# M460_v1 register map
File version: 1.0
Registers are 32-bit, read-write, reset 0x0 unless marked. A register's access mark holds for its fields unless they carry their own. Offsets are from the block's base; [hi:lo] are bit positions; {n}, {i} and the like mark numbered series; 'fields as' and 'values as' point back to an identical list.

## TMR01 — TIMER Register Map
Base 0x40050000
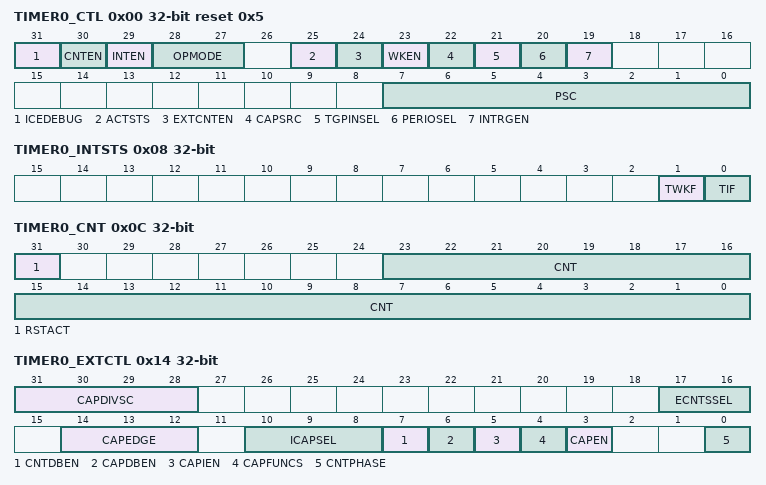
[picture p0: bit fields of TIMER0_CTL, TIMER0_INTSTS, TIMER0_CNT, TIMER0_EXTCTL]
0x00 TIMER0_CTL reset 0x5 — Timer0 Control Register
  [31] ICEDEBUG — ICE Debug Mode Acknowledge Disable Bit (Write Protect). TIMER counter will keep going no matter CPU is held by ICE or not. Note: This bit is write protected. Refer to the SYS_REGLCTL register.
    0=ICE debug mode acknowledgement effects TIMER counting; 1=ICE debug mode acknowledgement Disabled
  [30] CNTEN — Timer Counting Enable Bit. Note 3: Set enable/disable this bit needs 2 * TMR_CLK period to become active, user can read ACTSTS (TIMERx_CTL[25]) to check enable/disable command is completed or not.
    0=Stops/Suspends counting; 1=Starts counting
  [29] INTEN — Timer Time-out Interrupt Enable Bit. Note: If this bit is enabled, when the timer time-out interrupt flag TIF is set to 1, the timer interrupt signal is generated and inform to CPU.
    0=Timer time-out interrupt Disabled; 1=Timer time-out interrupt Enabled
  [28:27] OPMODE — Timer Counting Mode Select
    0=The timer controller is operated in One-shot mode; 1=The timer controller is operated in Periodic mode; 2=The timer controller is operated in Toggle-output mode; 3=The timer controller is operated in Continuous Counting mode
  [25] ACTSTS ro — Timer Active Status Bit (Read Only). This bit indicates the 24-bit up counter status. Note: This bit may active when CNT 0 transition to CNT 1.
    0=24-bit up counter is not active; 1=24-bit up counter is active
  [24] EXTCNTEN — Event Counter Mode Enable Bit. This bit is for event counting function enabled. Note: When timer is used as an event counter, this bit should be set to 1 and select PCLK as timer clock source.
    0=Event counter mode Disabled; 1=Event counter mode Enabled
  [23] WKEN — Wake-up Function Enable Bit. If this bit is set to 1, while timer interrupt flag TIF (TIMERx_INTSTS[0]) is 1 and INTEN (TIMERx_CTL[29]) is enabled, the timer interrupt signal will generate a wake-up trigger event to CPU.
    0=Wake-up function Disabled if timer interrupt signal generated; 1=Wake-up function Enabled if timer interrupt signal generated
  [22] CAPSRC — Capture Source Selection
    0=Capture Function source is from TMx_EXT (x= 0~3) pin; 1=Capture Function source is from internal ACMP output signal, internal clock source (HIRC, LIRC) or external clock (HXT, LXT)
  [21] TGPINSEL — Toggle-output Pin Select
    0=Toggle mode output to TMx (Timer Event Counter Pin); 1=Toggle mode output to TMx_EXT (Timer External Capture Pin)
  [20] PERIOSEL — Periodic Mode Behavior Selection Enable Bit. If updated CMPDAT value CNT, CNT will be reset to default value.
    0=The behavior selection in periodic mode is Disabled; 1=The behavior selection in periodic mode is Enabled
  [19] INTRGEN — Inter-Timer Trigger Mode Enable Bit. Setting this bit will enable the inter-timer trigger capture function. The Timer0/2 will be in event counter mode and counting with external clock source or event.Also, Timer1/3 will be in trigger-counting mode of capture function. Note: For Timer1/3, this bit is ignored and the read back value is always 0.
    0=Inter-Timer Trigger Capture mode Disabled; 1=Inter-Timer Trigger Capture mode Enabled
  [7:0] PSC — Prescale Counter. Note: Update prescale counter value will reset internal 8-bit prescale counter and 24-bit up counter value.
0x04 TIMER0_CMP — Timer0 Comparator Register
  [23:0] CMPDAT — Timer Comparator Value. CMPDAT is a 24-bit compared value register. When the internal 24-bit up counter value is equal to CMPDAT value, the TIF (TIMERx_INTSTS [0] Timer Interrupt Flag) will be set to 1. Note 1: Never write 0x0 or 0x1 in CMPDAT field, or the core will run into unknown state. Note 2: When timer is operating at continuous counting mode, the 24-bit up counter will keep counting continuously even if user writes a new value into CMPDAT field. But if timer is operating at other modes, the 24-bit up counter will restart counting from 0 and using newest CMPDAT value to be the timer compared value while user writes a new value into CMPDAT field.
0x08 TIMER0_INTSTS — Timer0 Interrupt Status Register
  [1] TWKF — Timer Wake-up Flag. This bit indicates the interrupt wake-up flag status of timer. Note: This bit is cleared by writing 1 to it.
    0=Timer does not cause CPU wake-up; 1=CPU wake-up from Idle or Power-down mode if timer time-out interrupt signal generated
  [0] TIF — Timer Interrupt Flag. This bit indicates the interrupt flag status of timer while 24-bit timer up counter CNT (TIMERx_CNT[23:0]) value reaches CMPDAT (TIMERx_CMP[23:0]) value. Note: This bit is cleared by writing 1 to it.
    0=No effect; 1=CNT value matches the CMPDAT value
0x0C TIMER0_CNT — Timer0 Data Register
  [31] RSTACT ro — Timer Data Register Reset Active (Read Only). This bit indicates if the counter reset operation active. When user writes this CNT register, timer starts to reset its internal 24-bit timer up-counter to 0 and reload 8-bit pre-scale counter. At the same time, timer set this flag to 1 to indicate the counter reset operation is in progress. Once the counter reset operation done, timer clear this bit to 0 automatically.
    0=Reset operation is done; 1=Reset operation triggered by writing TIMERx_CNT is in progress
  [23:0] CNT — Timer Data Register. Read operation. Read this register to get CNT value. For example: If EXTCNTEN (TIMERx_CTL[24]) is 0, user can read CNT value for getting current 24-bit counter value. If EXTCNTEN (TIMERx_CTL[24]) is 1, user can read CNT value for getting current 24-bit event input counter value. Write operation. Writing any value to this register will reset current CNT value to 0 and reload internal 8-bit prescale counter.
0x10 TIMER0_CAP ro — Timer0 Capture Data Register
  [23:0] CAPDAT — Timer Capture Data Register. When CAPEN (TIMERx_EXTCTL[3]) bit is set, the transition on the capture source matches the CAPEDGE (TIMERx_EXTCTL[14:12]) setting, CAPIF (TIMERx_EINTSTS[0]) will be set to 1 and the current timer counter value CNT (TIMERx_CNT[23:0]) will be auto-loaded into this CAPDAT field.
0x14 TIMER0_EXTCTL — Timer0 External Control Register
  [31:28] CAPDIVSC — Timer Capture Source Divider Scale. These bits indicate the divide scale for capture source divider. Note: Sets CAPSRC (TIMERx_CTL[22]) and ICAPSEL (TIMERx_EXTCTL[10:8]) to select capture source.
    0=Capture source/1; 1=Capture source/2; 2=Capture source/4; 3=Capture source/8; 4=Capture source/16; 5=Capture source/32; 6=Capture source/64; 7=Capture source/128; 8=Capture source/256
  [17:16] ECNTSSEL — Event Counter Source Selection to Trigger Event Counter Function
    0=Event Counter input source is from external TMx (x= 0~3) pin; 1=Event Counter input source is from internal USB internal SOF output signal; 2=Event Counter input source is from internal ACMP0 output signal; 3=Event Counter input source is from internal ACMP1 output signal
  [14:12] CAPEDGE — Timer Capture Edge Detect. When the first capture event is generated, the CNT (TIMERx_CNT[23:0]) will be reset to 0 and first CAPDAT (TIMERx_CAP[23:0]) should be to 0. Note: Set CAPSRC (TIMERx_CTL[22]) and ICAPSEL (TIMERx_EXTCTL[10:8]) to select capture source.
    0=Capture event occurred when detect falling edge transfer on capture source; 1=Capture event occurred when detect rising edge transfer on capture source; 2=Capture event occurred when detect both falling and rising edge transfer on capture source, and the first capture event occurred at falling edge transfer; 3=Capture event occurred when detect both rising and falling edge transfer on capture source, and the first capture event occurred at rising edge transfer; 6=First capture event occurred at falling edge, follows capture events are at rising edge transfer on capture source; 7=First capture event occurred at rising edge, follows capture events are at falling edge transfer on capture source
  [10:8] ICAPSEL — Internal Capture Source Select. Note: These bits only available when CAPSRC (TIMERx_CTL[22]) is 1.
    0=Capture Function source is from internal ACMP0 output signal; 1=Capture Function source is from internal ACMP1 output signal; 2=Capture Function source is from HXT; 3=Capture Function source is from LXT; 4=Capture Function source is from HIRC; 5=Capture Function source is from LIRC
  [7] CNTDBEN — Timer External Counter Pin De-bounce Enable Bit. Note: If this bit is enabled, the edge detection of TMx pin is detected with de-bounce circuit.
    0=TMx (x= 0~3) pin de-bounce Disabled; 1=TMx (x= 0~3) pin de-bounce Enabled
  [6] CAPDBEN — Timer Capture De-bounce Enable Bit. Note: If this bit is enabled, the edge detection of TMx_EXT pin or ACMP output is detected with de-bounce circuit.
    0=TMx_EXT (x= 0~3) pin de-bounce or ACMP output de-bounce Disabled; 1=TMx_EXT (x= 0~3) pin de-bounce or ACMP output de-bounce Enabled
  [5] CAPIEN — Timer Capture Interrupt Enable Bit
    0=TMx_EXT (x= 0~3) pin, ACMP, internal clock, or external clock detection Interrupt Disabled; 1=TMx_EXT (x= 0~3) pin, ACMP, internal clock, or external clock detection Interrupt Enabled
  [4] CAPFUNCS — Capture Function Selection. Note 1: When CAPFUNCS is 0 and CAPIF becomes 1, the current 24-bit timer counter value (CNT value) will be saved to CAPDAT field. Note 2: When CAPFUNCS is 1 and CAPIF becomes 1, the current 24-bit timer counter value (CNT value) will be saved to CAPDAT field then CNT value will be reset to 0 immediately.
    0=Capture Mode Enabled; 1=Capture and Reset Mode Enabled
  [3] CAPEN — Timer Capture Function Enable Bit. This bit enables the capture input function.
    0=Timer capture function Disabled; 1=Timer capture function Enabled
  [0] CNTPHASE — Timer External Count Phase
    0=A falling edge of external counting pin will be counted; 1=A rising edge of external counting pin will be counted
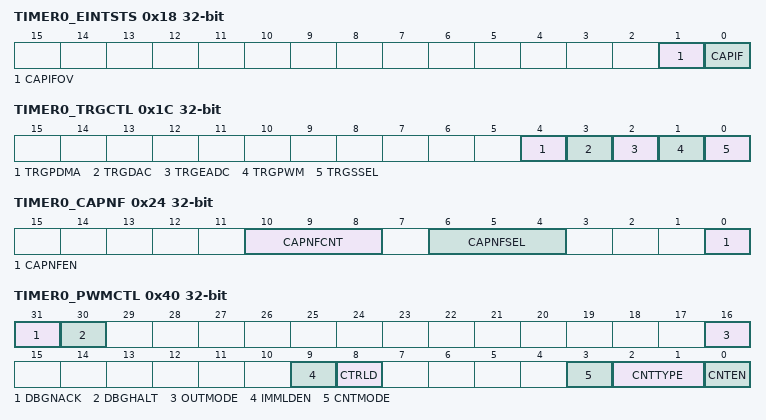
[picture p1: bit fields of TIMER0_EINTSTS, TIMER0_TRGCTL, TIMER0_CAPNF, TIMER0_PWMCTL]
0x18 TIMER0_EINTSTS — Timer0 External Interrupt Status Register
  [1] CAPIFOV ro — Capture Latch Interrupt Flag Overrun Status (Read Only). Note: This bit will be cleared automatically when user clears corresponding CAPIF.
    0=Capture latch happened when the corresponding CAPIF is 0; 1=Capture latch happened when the corresponding CAPIF is 1
  [0] CAPIF — Timer Capture Interrupt Flag. This bit indicates the timer capture interrupt flag status. Note 1: This bit is cleared by writing 1 to it. Note 2: When CAPEN (TIMERx_EXTCTL[3]) bit is set, the transition on the capture source matches the CAPEDGE (TIMERx_EXTCTL[14:12]) setting, this bit will be set to 1 by hardware. Note 3: There is a new incoming capture event detected before CPU clearing the CAPIF status. If the above condition occurred, the timer will keep register TIMERx_CAP unchanged and drop the new capture value.
    0=TMx_EXT (x= 0~3) pin, ACMP, internal clock, or external clock capture interrupt did not occur; 1=TMx_EXT (x= 0~3) pin, ACMP, internal clock, or external clock capture interrupt occurred
0x1C TIMER0_TRGCTL — Timer0 Trigger Control Register
  [4] TRGPDMA — Trigger PDMA Enable Bit. If this bit is set to 1, each timer time-out event or capture event can be triggered PDMA transfer.
    0=Timer interrupt trigger PDMA Disabled; 1=Timer interrupt trigger PDMA Enabled
  [3] TRGDAC — Trigger DAC Enable Bit. If this bit is set to 1, timer time-out interrupt or capture interrupt can be triggered DAC conversion.
    0=Timer interrupt trigger DAC Disabled; 1=Timer interrupt trigger DAC Enabled
  [2] TRGEADC — Trigger EADC Enable Bit. If this bit is set to 1, each timer time-out event or capture event can be triggered EADC conversion.
    0=Timer interrupt trigger EADC Disabled; 1=Timer interrupt trigger EADC Enabled
  [1] TRGPWM — Trigger EPWM and BPWM Enable Bit. If this bit is set to 1, each timer time-out event or capture event can be as EPWM and BPWM counter clock source.
    0=Timer interrupt signal as EPWM and BPWM counter clock source Disabled; 1=Timer interrupt signal as EPWM and BPWM counter clock source Enabled
  [0] TRGSSEL — Trigger Source Select Bit. This bit is used to select internal trigger source is form timer time-out interrupt signal or capture interrupt signal.
    0=Time-out interrupt signal is used to internal trigger EPWM, BPWM, PDMA, DAC, and EADC; 1=Capture interrupt signal is used to internal trigger EPWM, BPWM, PDMA, DAC, and EADC
0x20 TIMER0_ALTCTL — Timer0 Alternative Control Register
  [0] FUNCSEL — Function Selection. Note: When the timer is used as PWM, the clock source of time controller will be forced to PCLKx automatically.
    0=Timer controller is used as timer function; 1=Timer controller is used as PWM function
0x24 TIMER0_CAPNF — Timer0 Capture Input Noise Filter Register
  [10:8] CAPNFCNT — Capture Edge Detector Noise Filter Count. These bits control the capture filter counter to count from 0 to CAPNFCNT.
  [6:4] CAPNFSEL — Capture Edge Detector Noise Filter Clock Selection
    0=Noise filter clock is PCLKx; 1=Noise filter clock is PCLKx/2; 2=Noise filter clock is PCLKx/4; 3=Noise filter clock is PCLKx/8; 4=Noise filter clock is PCLKx/16; 5=Noise filter clock is PCLKx/32; 6=Noise filter clock is PCLKx/64; 7=Noise filter clock is PCLKx/128
  [0] CAPNFEN — Capture Noise Filter Enable
    0=Capture Noise Filter function Disabled; 1=Capture Noise Filter function Enabled
0x40 TIMER0_PWMCTL — Timer0 PWM Control Register
  [31] DBGNACK — ICE Debug Mode Acknowledge Disable Bit (Write Protect). PWM output pin will keep output no matter ICE debug mode acknowledged or not. Note: This bit is write protected. Refer toSYS_REGLCTL register.
    0=ICE debug mode acknowledgement effects PWM output; 1=ICE debug mode acknowledgement disabled
  [30] DBGHALT — ICE Debug Mode Counter Halt (Write Protect). If debug mode counter halt is enabled, PWM counter will keep current value until exit ICE debug mode. Note: This bit is write protected. Refer toSYS_REGLCTL register.
    0=ICE debug mode counter halt disable; 1=ICE debug mode counter halt enable
  [16] OUTMODE — PWM Output Mode. This bit controls the output mode of corresponding PWM channel.
    0=PWM independent mode; 1=PWM complementary mode
  [9] IMMLDEN — Immediately Load Enable Bit. Note: If IMMLDEN is enabled, CTRLD will be invalid.
    0=PERIOD will load to PBUF when current PWM period is completed no matter CTRLD is enabled/disabled. If CTRLD is disabled, CMP will load to CMPBUF when current PWM period is completed; if CTRLD is enabled in up-down count type, CMP will load to CMPBUF at the center point of current period; 1=PERIOD/CMP will load to PBUF/CMPBUF immediately when user writes PERIOD/CMP and current counter count is completed
  [8] CTRLD — Center Re-load. In up-down count type, PERIOD will load to PBUF when current PWM period is completed always and CMP will load to CMPBUF at the center point of current period.
  [3] CNTMODE — PWM Counter Mode
    0=Auto-reload mode; 1=One-shot mode
  [2:1] CNTTYPE — PWM Counter Behavior Type
    0=Up count type; 1=Down count type; 2=Up-down count type
  [0] CNTEN — PWM Counter Enable Bit
    0=PWM counter and clock prescale Stop Running; 1=PWM counter and clock prescale Start Running
0x44 TIMER0_PWMCLKSRC — Timer0 PWM Counter Clock Source Register
  [2:0] CLKSRC — PWM Counter Clock Source Select. The PWM counter clock source can be selected from TMRx_CLK or internal timer time-out or capture event. Note: If TIMER0 PWM function is enabled, the PWM counter clock source can be selected from TMR0_CLK, TIMER1 interrupt events, TIMER2 interrupt events, or TIMER3 interrupt events.
    0=TMRx_CLK; {v}=Internal TIMER{v-1} time-out or capture event (v=1..4)
0x48 TIMER0_PWMCLKPSC — Timer0 PWM Counter Clock Pre-scale Register
  [11:0] CLKPSC — PWM Counter Clock Pre-scale. The active clock of PWM counter is decided by counter clock prescale and divided by (CLKPSC + 1). If CLKPSC is 0, then there is no scaling in PWM counter clock source.
0x4C TIMER0_PWMCNTCLR — Timer0 PWM Clear Counter Register
  [0] CNTCLR — Clear PWM Counter Control Bit. It is automatically cleared by hardware.
    0=No effect; 1=Clear 16-bit PWM counter to 0x10000 in up and up-down count type and reset counter value to PERIOD in down count type
0x50 TIMER0_PWMPERIOD
  [15:0] PERIOD — PWM Period Register. In up count type: PWM counter counts from 0 to PERIOD, and restarts from 0. In down count type: PWM counter counts from PERIOD to 0, and restarts from PERIOD. In up-down count type: PWM counter counts from 0 to PERIOD, then decrements to 0 and repeats again. In up and down count type: Note: User should take care DIRF (TIMERx_PWMCNT[16]) bit in up/down/up-down count type to monitor current counter direction in each count type.
0x54 TIMER0_PWMCMPDAT — Timer0 PWM Comparator Register
  [15:0] CMP — PWM Comparator Register. PWM CMP is used to compare with PWM CNT to generate PWM output waveform, interrupt events and trigger EADC to start conversion.
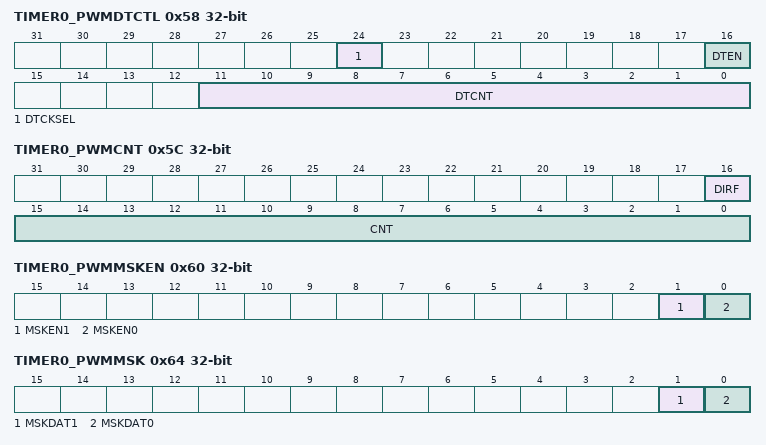
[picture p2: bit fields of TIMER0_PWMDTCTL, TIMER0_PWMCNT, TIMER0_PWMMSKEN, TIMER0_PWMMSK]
0x58 TIMER0_PWMDTCTL — Timer0 PWM Dead-Time Control Register
  [24] DTCKSEL — Dead-time Clock Select (Write Protect). Note: This bit is write protected. Refer toSYS_REGLCTL register.
    0=Dead-time clock source from TMRx_PWMCLK without counter clock prescale; 1=Dead-time clock source from TMRx_PWMCLK with counter clock prescale
  [16] DTEN — Enable Dead-time Insertion for PWMx_CH0 and PWMx_CH1 (Write Protect). Dead-time insertion function is only active when PWM complementary mode is enabled. If dead- time insertion is inactive, the outputs of PWMx_CH0 and PWMx_CH1 are complementary without any delay. Note: This bit is write protected. Refer toSYS_REGLCTL register.
    0=Dead-time insertion Disabled on the pin pair; 1=Dead-time insertion Enabled on the pin pair
  [11:0] DTCNT — Dead-time Counter (Write Protect). The dead-time can be calculated from the following two formulas: Note: This bit is write protected. Refer toSYS_REGLCTL register.
0x5C TIMER0_PWMCNT ro — Timer0 PWM Counter Register
  [16] DIRF — PWM Counter Direction Indicator Flag (Read Only)
    0=Counter is active in down count; 1=Counter is active up count
  [15:0] CNT — PWM Counter Value Register (Read Only). User can monitor CNT to know the current counter value in 16-bit period counter.
0x60 TIMER0_PWMMSKEN — Timer0 PWM Output Mask Enable Register
  [1] MSKEN1 — PWMx_CH1 Output Mask Enable Bit. The PWMx_CH1 output signal will be masked when this bit is enabled. The PWMx_CH1 will output MSKDAT1 (TIMERx_PWMMSK[1]) data.
    0=PWMx_CH1 output signal is non-masked; 1=PWMx_CH1 output signal is masked and output MSKDAT1 data
  [0] MSKEN0 — PWMx_CH0 Output Mask Enable Bit. The PWMx_CH0 output signal will be masked when this bit is enabled. The PWMx_CH0 will output MSKDAT0 (TIMERx_PWMMSK[0]) data.
    0=PWMx_CH0 output signal is non-masked; 1=PWMx_CH0 output signal is masked and output MSKDAT0 data
0x64 TIMER0_PWMMSK — Timer0 PWM Output Mask Data Control Register
  [1] MSKDAT1 — PWMx_CH1 Output Mask Data Control Bit
    0=Output logic Low to PWMx_CH1; 1=Output logic High to PWMx_CH1
  [0] MSKDAT0 — PWMx_CH0 Output Mask Data Control Bit
    0=Output logic Low to PWMx_CH0; 1=Output logic High to PWMx_CH0
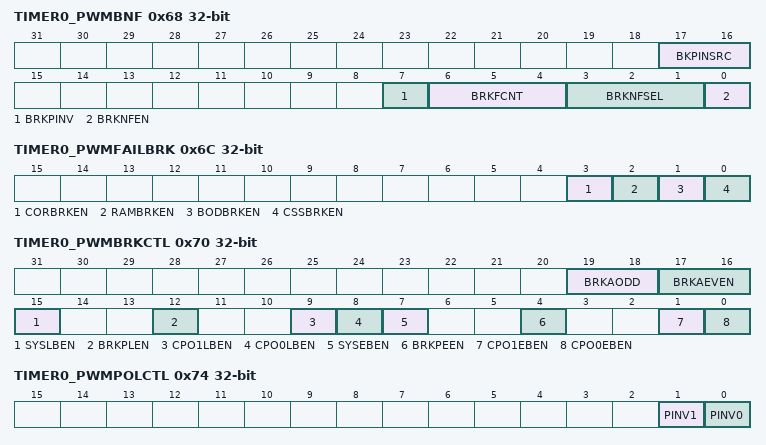
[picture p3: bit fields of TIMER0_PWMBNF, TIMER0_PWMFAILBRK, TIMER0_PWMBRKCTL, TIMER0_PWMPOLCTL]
0x68 TIMER0_PWMBNF — Timer0 PWM Brake Pin Noise Filter Register
  [17:16] BKPINSRC — Brake Pin Source Select
    0=Brake pin source comes from PWM0_BRAKE0 pin; 1=Brake pin source comes from PWM0_BRAKE1 pin; 2=Brake pin source comes from PWM1_BRAKE0 pin; 3=Brake pin source comes from PWM1_BRAKE1 pin
  [7] BRKPINV — Brake Pin Detection Value Control Bit
    0=Brake pin event will be detected if PWMx_BRAKEy pin status transfer from low to high in edge-detect, or pin status is high in level-detect; 1=Brake pin event will be detected if PWMx_BRAKEy pin status transfer from high to low in edge-detect, or pin status is low in level-detect
  [6:4] BRKFCNT — Brake Pin Noise Filter Count. The fields are used to control the active noise filter sample time.
  [3:1] BRKNFSEL — Brake Pin Noise Filter Clock Selection
    values as TIMER0_CAPNF.CAPNFSEL
  [0] BRKNFEN — Brake Pin Noise Filter Enable Bit
    0=Pin noise filter detect of PWMx_BRAKEy Disabled; 1=Pin noise filter detect of PWMx_BRAKEy Enabled
0x6C TIMER0_PWMFAILBRK — Timer0 PWM System Fail Brake Control Register
  [3] CORBRKEN — Core Lockup Detection Trigger PWM Brake Function Enable Bit
    0=Brake Function triggered by core lockup event Disabled; 1=Brake Function triggered by core lockup event Enabled
  [2] RAMBRKEN — SRAM Parity Error Detection Trigger PWM Brake Function Enable Bit
    0=Brake Function triggered by SRAM parity error detection Disabled; 1=Brake Function triggered by SRAM parity error detection Enabled
  [1] BODBRKEN — Brown-out Detection Trigger PWM Brake Function Enable Bit
    0=Brake Function triggered by BOD event Disabled; 1=Brake Function triggered by BOD event Enabled
  [0] CSSBRKEN — Clock Security System Detection Trigger PWM Brake Function Enable Bit
    0=Brake Function triggered by clock fail detection Disabled; 1=Brake Function triggered by clock fail detection Enabled
0x70 TIMER0_PWMBRKCTL — Timer0 PWM Brake Control Register
  [19:18] BRKAODD — PWM Brake Action Select for PWMx_CH1 (Write Protect). Note: This bit is write protected. Refer toSYS_REGLCTL register.
    0=PWMx_BRAKEy brake event will not affect PWMx_CH1 output; 1=PWMx_CH1 output tri-state when PWMx_BRAKEy brake event happened; 2=PWMx_CH1 output low level when PWMx_BRAKEy brake event happened; 3=PWMx_CH1 output high level when PWMx_BRAKEy brake event happened
  [17:16] BRKAEVEN — PWM Brake Action Select for PWMx_CH0 (Write Protect). Note: This bit is write protected. Refer toSYS_REGLCTL register.
    0=PWMx_BRAKEy brake event will not affect PWMx_CH0 output; 1=PWMx_CH0 output tri-state when PWMx_BRAKEy brake event happened; 2=PWMx_CH0 output low level when PWMx_BRAKEy brake event happened; 3=PWMx_CH0 output high level when PWMx_BRAKEy brake event happened
  [15] SYSLBEN — Enable System Fail As Level-detect Brake Source (Write Protect). Note: This bit is write protected. Refer toSYS_REGLCTL register.
    0=System fail condition as level-detect brake source Disabled; 1=System fail condition as level-detect brake source Enabled
  [12] BRKPLEN — Enable PWMx_BRAKEy Pin As Level-detect Brake Source (Write Protect). Note: This bit is write protected. Refer toSYS_REGLCTL register.
    0=PWMx_BRAKEy pin event as level-detect brake source Disabled; 1=PWMx_BRAKEy pin event as level-detect brake source Enabled
  [9] CPO1LBEN — Enable Internal ACMP1_O Digital Output As Level-detect Brake Source (Write Protect). Note 1: Only internal ACMP1_O signal from low to high will be detected as brake event. Note 2: This bit is write protected. Refer toSYS_REGLCTL register.
    0=Internal ACMP1_O signal as level-detect brake source Disabled; 1=Internal ACMP1_O signal as level-detect brake source Enabled
  [8] CPO0LBEN — Enable Internal ACMP0_O Digital Output As Level-detect Brake Source (Write Protect). Note 1: Only internal ACMP0_O signal from low to high will be detected as brake event. Note 2: This bit is write protected. Refer toSYS_REGLCTL register.
    0=Internal ACMP0_O signal as level-detect brake source Disabled; 1=Internal ACMP0_O signal as level-detect brake source Enabled
  [7] SYSEBEN — Enable System Fail As Edge-detect Brake Source (Write Protect). Note: This bit is write protected. Refer toSYS_REGLCTL register.
    0=System fail condition as edge-detect brake source Disabled; 1=System fail condition as edge-detect brake source Enabled
  [4] BRKPEEN — Enable PWMx_BRAKEy Pin As Edge-detect Brake Source (Write Protect). Note: This bit is write protected. Refer toSYS_REGLCTL register.
    0=PWMx_BRAKEy pin event as edge-detect brake source Disabled; 1=PWMx_BRAKEy pin event as edge-detect brake source Enabled
  [1] CPO1EBEN — Enable Internal ACMP1_O Digital Output As Edge-detect Brake Source (Write Protect). Note 1: Only internal ACMP1_O signal from low to high will be detected as brake event. Note 2: This bit is write protected. Refer toSYS_REGLCTL register.
    0=Internal ACMP1_O signal as edge-detect brake source Disabled; 1=Internal ACMP1_O signal as edge-detect brake source Enabled
  [0] CPO0EBEN — Enable Internal ACMP0_O Digital Output As Edge-detect Brake Source (Write Protect). Note 1: Only internal ACMP0_O signal from low to high will be detected as brake event. Note 2: This bit is write protected. Refer toSYS_REGLCTL register.
    0=Internal ACMP0_O signal as edge-detect brake source Disabled; 1=Internal ACMP0_O signal as edge-detect brake source Enabled
0x74 TIMER0_PWMPOLCTL — Timer0 PWM Pin Output Polar Control Register
  [1] PINV1 — PWMx_CH1 Output Pin Polar Control Bit. The bit is used to control polarity state of PWMx_CH1 output pin.
    0=PWMx_CH1 output pin polar inverse Disabled; 1=PWMx_CH1 output pin polar inverse Enabled
  [0] PINV0 — PWMx_CH0 Output Pin Polar Control Bit. The bit is used to control polarity state of PWMx_CH0 output pin.
    0=PWMx_CH0 output pin polar inverse Disabled; 1=PWMx_CH0 output pin polar inverse Enabled
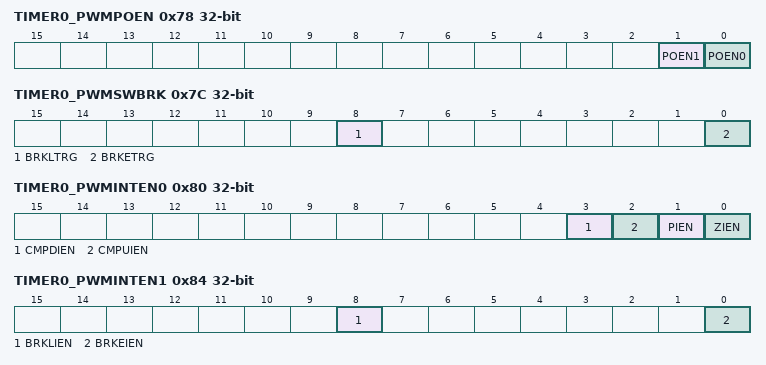
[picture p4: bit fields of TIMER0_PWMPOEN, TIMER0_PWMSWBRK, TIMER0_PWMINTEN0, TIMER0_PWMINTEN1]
0x78 TIMER0_PWMPOEN — Timer0 PWM Pin Output Enable Register
  [1] POEN1 — PWMx_CH1 Output Pin Enable Bit
    0=PWMx_CH1 pin at tri-state mode; 1=PWMx_CH1 pin in output mode
  [0] POEN0 — PWMx_CH0 Output Pin Enable Bit
    0=PWMx_CH0 pin at tri-state mode; 1=PWMx_CH0 pin in output mode
0x7C TIMER0_PWMSWBRK wo — Timer0 PWM Software Trigger Brake Control Register
  [8] BRKLTRG — Software Trigger Level-detect Brake Source (Write Only) (Write Protect). Write 1 to this bit will trigger PWM level-detect brake source, then BRKLIF0 and BRKLIF1 will be set to 1 automatically in TIMERx_PWMINTSTS1 register. Note: This bit is write protected. Refer toSYS_REGLCTL register.
  [0] BRKETRG — Software Trigger Edge-detect Brake Source (Write Only) (Write Protect). Write 1 to this bit will trigger PWM edge-detect brake source, then BRKEIF0 and BRKEIF1 will be set to 1 automatically in TIMERx_PWMINTSTS1 register. Note: This bit is write protected. Refer toSYS_REGLCTL register.
0x80 TIMER0_PWMINTEN0 — Timer0 PWM Interrupt Enable Register 0
  [3] CMPDIEN — PWM Compare Down Count Interrupt Enable Bit
    0=Compare down count interrupt Disabled; 1=Compare down count interrupt Enabled
  [2] CMPUIEN — PWM Compare Up Count Interrupt Enable Bit
    0=Compare up count interrupt Disabled; 1=Compare up count interrupt Enabled
  [1] PIEN — PWM Period Point Interrupt Enable Bit. Note: In up-down count type, period point means the center point of current PWM period.
    0=Period point interrupt Disabled; 1=Period point interrupt Enabled
  [0] ZIEN — PWM Zero Point Interrupt Enable Bit
    0=Zero point interrupt Disabled; 1=Zero point interrupt Enabled
0x84 TIMER0_PWMINTEN1 — Timer0 PWM Interrupt Enable Register 1
  [8] BRKLIEN — PWM Level-detect Brake Interrupt Enable Bit (Write Protect). Note: This bit is write protected. Refer toSYS_REGLCTL register.
    0=PWM level-detect brake interrupt Disabled; 1=PWM level-detect brake interrupt Enabled
  [0] BRKEIEN — PWM Edge-detect Brake Interrupt Enable Bit (Write Protect). Note: This bit is write protected. Refer toSYS_REGLCTL register.
    0=PWM edge-detect brake interrupt Disabled; 1=PWM edge-detect brake interrupt Enabled
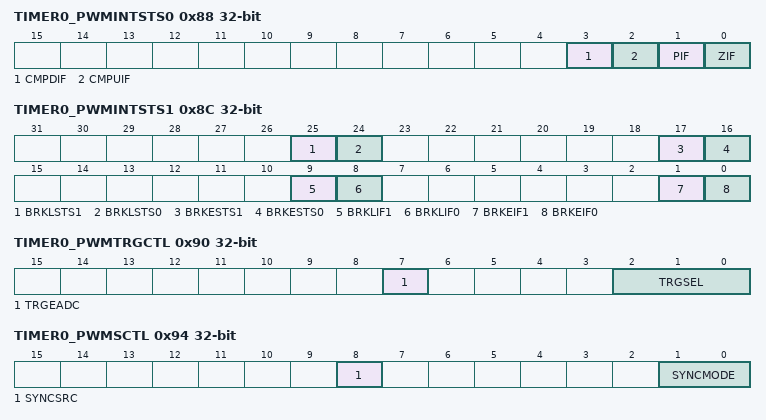
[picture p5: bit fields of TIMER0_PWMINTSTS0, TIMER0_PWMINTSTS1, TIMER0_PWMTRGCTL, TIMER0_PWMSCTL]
0x88 TIMER0_PWMINTSTS0 — Timer0 PWM Interrupt Status Register 0
  [3] CMPDIF — PWM Compare Down Count Interrupt Flag. This bit is set by hardware when TIMERx_PWM counter in down count direction and reaches CMP. Note 1: If CMP is equal to PERIOD, there is no CMPDIF flag in down count type. Note 2: This bit is cleared by writing 1 to it.
  [2] CMPUIF — PWM Compare Up Count Interrupt Flag. This bit is set by hardware when TIMERx_PWM counter in up count direction and reaches CMP. Note 1: If CMP is equal to PERIOD, there is no CMPUIF flag in up count type and up-down count type. Note 2: This bit is cleared by writing 1 to it.
  [1] PIF — PWM Period Point Interrupt Flag. This bit is set by hardware when TIMERx_PWM counter reaches PERIOD. Note 1: In up-down count type, PIF flag means the center point flag of current PWM period. Note 2: This bit is cleared by writing 1 to it.
  [0] ZIF — PWM Zero Point Interrupt Flag. This bit is set by hardware when TIMERx_PWM counter reaches 0. Note: This bit is cleared by writing 1 to it.
0x8C TIMER0_PWMINTSTS1 — Timer0 PWM Interrupt Status Register 1
  [25] BRKLSTS1 ro — Level-detect Brake Status of PWMx_CH1 (Read Only). Note: If TIMERx_PWM level-detect brake source has released, both PWMx_CH0 and PWMx_CH1 will release brake state when current PWM period finished and resume PWMx_CH0 and PWMx_CH1 output waveform start from next full PWM period.
    0=PWMx_CH1 level-detect brake state is released; 1=PWMx_CH1 at level-detect brake state
  [24] BRKLSTS0 ro — Level-detect Brake Status of PWMx_CH0 (Read Only). Note: If TIMERx_PWM level-detect brake source has released, both PWMx_CH0 and PWMx_CH1 will release brake state when current PWM period finished and resume PWMx_CH0 and PWMx_CH1 output waveform start from next full PWM period.
    0=PWMx_CH0 level-detect brake state is released; 1=PWMx_CH0 at level-detect brake state
  [17] BRKESTS1 ro — Edge-detect Brake Status of PWMx_CH1 (Read Only). Note: User can set BRKEIF1 1 to clear BRKEIF1 flag and PWMx_CH1 will release brake state when current PWM period finished and resume PWMx_CH1 output waveform start from next full PWM period.
    0=PWMx_CH1 edge-detect brake state is released; 1=PWMx_CH1 at edge-detect brake state
  [16] BRKESTS0 ro — Edge -detect Brake Status of PWMx_CH0 (Read Only). Note: User can set BRKEIF0 1 to clear BRKEIF0 flag and PWMx_CH0 will release brake state when current PWM period finished and resume PWMx_CH0 output waveform start from next full PWM period.
    0=PWMx_CH0 edge-detect brake state is released; 1=PWMx_CH0 at edge-detect brake state
  [9] BRKLIF1 — Level-detect Brake Interrupt Flag on PWMx_CH1 (Write Protect). Note 1: This bit is cleared by writing 1 to it. Note 2: This bit is write protected. Refer to SYS_REGLCTL register.
    0=PWMx_CH1 level-detect brake event do not happened; 1=PWMx_CH1 level-detect brake event happened
  [8] BRKLIF0 — Level-detect Brake Interrupt Flag on PWMx_CH0 (Write Protect). Note 1: This bit is cleared by writing 1 to it. Note 2: This bit is write protected. Refer to SYS_REGLCTL register.
    0=PWMx_CH0 level-detect brake event do not happened; 1=PWMx_CH0 level-detect brake event happened
  [1] BRKEIF1 — Edge-detect Brake Interrupt Flag PWMx_CH1 (Write Protect). Note 1: This bit is cleared by writing 1 to it. Note 2: This bit is write protected. Refer to SYS_REGLCTL register.
    0=PWMx_CH1 edge-detect brake event do not happened; 1=PWMx_CH1 edge-detect brake event happened
  [0] BRKEIF0 — Edge-detect Brake Interrupt Flag on PWMx_CH0 (Write Protect). Note 1: This bit is cleared by writing 1 to it. Note 2: This bit is write protected. Refer to SYS_REGLCTL register.
    0=PWMx_CH0 edge-detect brake event do not happened; 1=PWMx_CH0 edge-detect brake event happened
0x90 TIMER0_PWMTRGCTL — Timer0 PWM Trigger Control Register
  [7] TRGEADC — PWM Counter Event Trigger EADC Conversion Enable Bit. Note: Set TRGSEL (TIMERx_PWMTRGCTL[2:0]) to select PWM trigger conversion source.
    0=PWM counter event trigger EADC conversion Disabled; 1=PWM counter event trigger EADC conversion Enabled
  [2:0] TRGSEL — PWM Counter Event Source Select to Trigger Conversion
    0=Trigger conversion at zero point (ZIF); 1=Trigger conversion at period point (PIF); 2=Trigger conversion at zero or period point (ZIF or PIF); 3=Trigger conversion at compare up count point (CMPUIF); 4=Trigger conversion at compare down count point (CMPDIF)
0x94 TIMER0_PWMSCTL — Timer0 PWM Synchronous Control Register
  [8] SYNCSRC — PWM Synchronous Counter Start/Clear Source Select. Note 1: If TIMER0/1/2/3 PWM counter synchronous source are from TIMER0, TIMER0_PWMSCTL[8], TIMER1_PWMSCTL[8], TIMER2_PWMSCTL[8] and TIMER3_PWMSCTL[8] should be 0. Note 2: If TIMER0/1/ PWM counter synchronous source are from TIMER0, TIMER0_PWMSCTL[8] and TIMER1_PWMSCTL[8] should be set 0, and TIMER2/3/ PWM counter synchronous source are from TIMER2, TIMER2_PWMSCTL[8] and TIMER3_PWMSCTL[8] should be set 1.
    0=Counter synchronous start/clear by trigger TIMER0_PWMSTRG STRGEN bit; 1=Counter synchronous start/clear by trigger TIMER2_PWMSTRG STRGEN bit
  [1:0] SYNCMODE — PWM Synchronous Mode Enable Select
    0=PWM synchronous function Disabled; 1=PWM synchronous counter start function Enabled; 3=PWM synchronous counter clear function Enabled
0x98 TIMER0_PWMSTRG wo — Timer0 PWM Synchronous Trigger Register
  [0] STRGEN — PWM Counter Synchronous Trigger Enable Bit (Write Only). PMW counter synchronous function is used to make selected PWM channels (including TIMER0/1/2/3 PWM, TIMER0/1 PWM and TIMER2/3 PWM) start counting or clear counter at the same time according to TIMERx_PWMSCTL setting. Note: This bit is only available in TIMER0 and TIMER2.
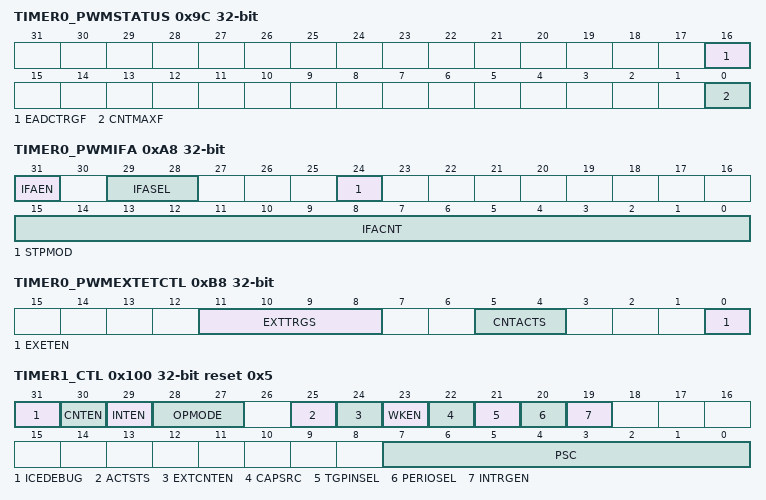
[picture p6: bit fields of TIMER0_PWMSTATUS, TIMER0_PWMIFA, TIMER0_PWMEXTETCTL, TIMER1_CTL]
0x9C TIMER0_PWMSTATUS
  [16] EADCTRGF — Trigger EADC Start Conversion Flag. Note: This bit is cleared by writing 1 to it.
    0=PWM counter event trigger EADC start conversion did not occurred; 1=PWM counter event trigger EADC start conversion occurred
  [0] CNTMAXF — PWM Counter Equal to 0xFFFF Flag. Note: This bit is cleared by writing 1 to it.
    0=The PWM counter value never reached its maximum value 0xFFFF; 1=The PWM counter value has reached its maximum value
0xA0 TIMER0_PWMPBUF ro — Timer0 PWM Period Buffer Register
  [15:0] PBUF — PWM Period Buffer Register (Read Only). Used as PERIOD active register.
0xA4 TIMER0_PWMCMPBUF ro — Timer0 PWM Comparator Buffer Register
  [15:0] CMPBUF — PWM Comparator Buffer Register (Read Only). Used as CMP active register.
0xA8 TIMER0_PWMIFA — Timer0 PWM Interrupt Flag Accumulator Register
  [31] IFAEN — PWM Interrupt Flag Accumulator Enable Bit
    0=PWM interrupt flag accumulator function Disabled; 1=PWM interrupt flag accumulator function Enabled
  [29:28] IFASEL — PWM Interrupt Flag Accumulator Source Select
    0=Accumulate at each PWM zero point; 1=Accumulate at each PWM period point; 2=Accumulate at each PWM up-count compared point; 3=Accumulate at each PWM down-count compared point
  [24] STPMOD — PWM Accumulator Stop Mode Enable Bit
    0=PWM interrupt accumulator event to stop counting Disabled; 1=PWM interrupt accumulator event to stop counting Enabled
  [15:0] IFACNT — PWM Interrupt Flag Accumulator Counter. This field sets the count number which defines (IFACNT+1) times of specify PWM interrupt occurs to set IFAIF bit to request the PWM accumulator interrupt. PWM accumulator flag (IFAIF) will be set in every (IFACNT+1) times during the the PWM counter operation.
0xAC TIMER0_PWMAINTSTS — Timer0 PWM Accumulator Interrupt Flag Register
  [0] IFAIF — PWM Interrupt Flag Accumulator Interrupt Flag. This bit is set by hardware when the accumulator value reaches (IFACNT+1). Note 1: This bit is cleared by writing 1 to it. Note 2: If APDMAEN (TIMERx_PWMAPDMACTL[0]) is set, this bit will be auto clear after PDMA transfer done.
0xB0 TIMER0_PWMAINTEN — Timer0 PWM Accumulator Interrupt Enable Register
  [0] IFAIEN — PWM Interrupt Flag Accumulator Interrupt Enable Bit
    0=Interrupt Flag Accumulator interrupt Disabled; 1=Interrupt Flag Accumulator interrupt Enabled
0xB4 TIMER0_PWMAPDMACTL — Timer0 PWM Accumulator PDMA Control Register
  [0] APDMAEN — PWM Accumulator PDMA Enable Bit
    0=PWM interrupt accumulator event to trigger PDMA transfer Disabled; 1=PWM interrupt accumulator event to trigger PDMA transfer Enabled
0xB8 TIMER0_PWMEXTETCTL — Timer0 PWM External Event Trigger Control Register
  [11:8] EXTTRGS — External Trigger Pin Selection
    {v}=Trigger source form INT{v} pin (v=0..7)
  [5:4] CNTACTS — Counter Action Selection
    0=External pin event to trigger PWM counter reset; 1=External pin event to trigger PWM counter start; 2=External pin event to trigger PWM counter reset and start
  [0] EXETEN — External Pin Event Trigger Enable Bit
    0=External pin event trigger function Disabled; 1=External pin event trigger function Enabled
0x100 TIMER1_CTL reset 0x5 — Timer1 Control Register
  fields as TIMER0_CTL
0x104 TIMER1_CMP — Timer1 Comparator Register
  fields as TIMER0_CMP
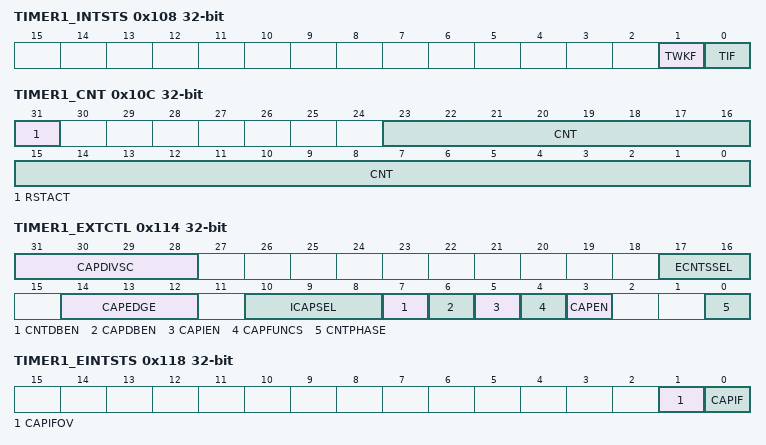
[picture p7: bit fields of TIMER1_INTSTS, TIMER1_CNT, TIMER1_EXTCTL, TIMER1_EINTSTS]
0x108 TIMER1_INTSTS — Timer1 Interrupt Status Register
  fields as TIMER0_INTSTS
0x10C TIMER1_CNT — Timer1 Data Register
  fields as TIMER0_CNT
0x110 TIMER1_CAP ro — Timer1 Capture Data Register
  fields as TIMER0_CAP
0x114 TIMER1_EXTCTL — Timer1 External Control Register
  fields as TIMER0_EXTCTL
0x118 TIMER1_EINTSTS — Timer1 External Interrupt Status Register
  fields as TIMER0_EINTSTS
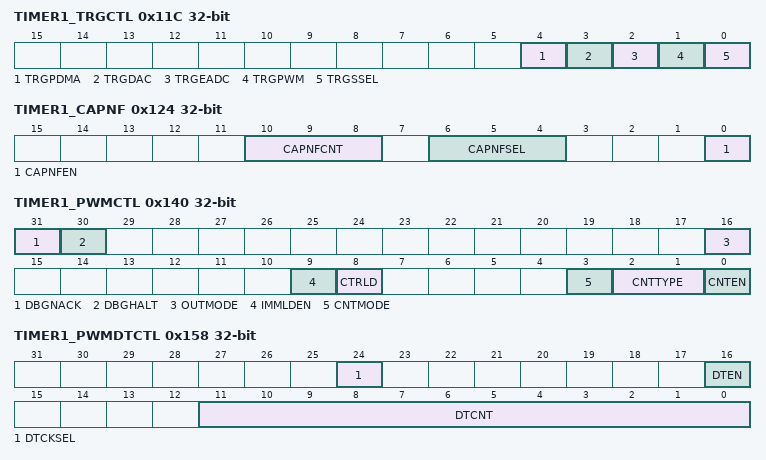
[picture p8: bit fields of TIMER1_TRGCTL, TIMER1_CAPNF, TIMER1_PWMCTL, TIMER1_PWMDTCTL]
0x11C TIMER1_TRGCTL — Timer1 Trigger Control Register
  fields as TIMER0_TRGCTL
0x120 TIMER1_ALTCTL — Timer1 Alternative Control Register
  fields as TIMER0_ALTCTL
0x124 TIMER1_CAPNF — Timer1 Capture Input Noise Filter Register
  fields as TIMER0_CAPNF
0x140 TIMER1_PWMCTL — Timer1 PWM Control Register
  fields as TIMER0_PWMCTL
0x144 TIMER1_PWMCLKSRC — Timer1 PWM Counter Clock Source Register
  fields as TIMER0_PWMCLKSRC
0x148 TIMER1_PWMCLKPSC — Timer1 PWM Counter Clock Pre-scale Register
  fields as TIMER0_PWMCLKPSC
0x14C TIMER1_PWMCNTCLR — Timer1 PWM Clear Counter Register
  fields as TIMER0_PWMCNTCLR
0x150 TIMER1_PWMPERIOD
  fields as TIMER0_PWMPERIOD
0x154 TIMER1_PWMCMPDAT — Timer1 PWM Comparator Register
  fields as TIMER0_PWMCMPDAT
0x158 TIMER1_PWMDTCTL — Timer1 PWM Dead-Time Control Register
  fields as TIMER0_PWMDTCTL
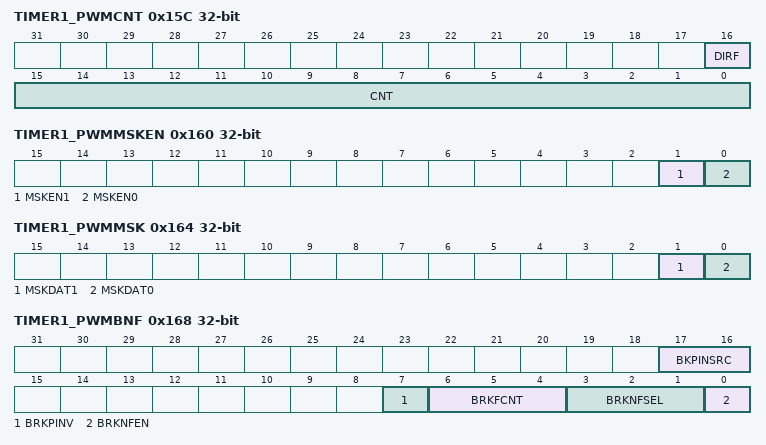
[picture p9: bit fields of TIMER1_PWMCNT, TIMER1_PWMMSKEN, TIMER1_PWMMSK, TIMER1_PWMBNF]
0x15C TIMER1_PWMCNT ro — Timer1 PWM Counter Register
  fields as TIMER0_PWMCNT
0x160 TIMER1_PWMMSKEN — Timer1 PWM Output Mask Enable Register
  fields as TIMER0_PWMMSKEN
0x164 TIMER1_PWMMSK — Timer1 PWM Output Mask Data Control Register
  fields as TIMER0_PWMMSK
0x168 TIMER1_PWMBNF — Timer1 PWM Brake Pin Noise Filter Register
  fields as TIMER0_PWMBNF
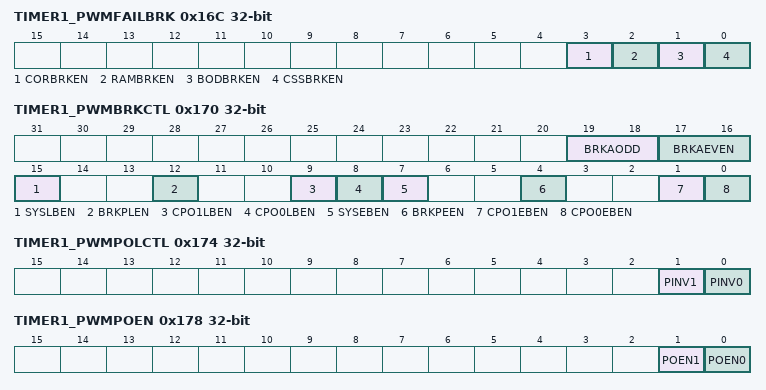
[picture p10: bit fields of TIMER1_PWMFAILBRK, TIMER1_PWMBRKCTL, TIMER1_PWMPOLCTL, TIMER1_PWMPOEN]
0x16C TIMER1_PWMFAILBRK — Timer1 PWM System Fail Brake Control Register
  fields as TIMER0_PWMFAILBRK
0x170 TIMER1_PWMBRKCTL — Timer1 PWM Brake Control Register
  fields as TIMER0_PWMBRKCTL
0x174 TIMER1_PWMPOLCTL — Timer1 PWM Pin Output Polar Control Register
  fields as TIMER0_PWMPOLCTL
0x178 TIMER1_PWMPOEN — Timer1 PWM Pin Output Enable Register
  fields as TIMER0_PWMPOEN
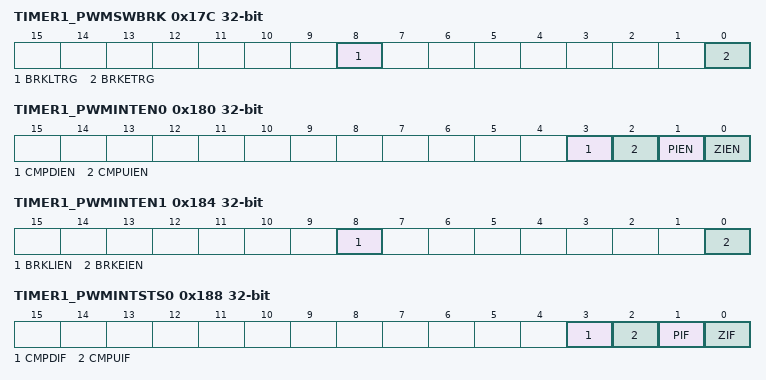
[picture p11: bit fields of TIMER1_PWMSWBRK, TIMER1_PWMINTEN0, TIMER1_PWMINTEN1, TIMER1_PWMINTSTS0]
0x17C TIMER1_PWMSWBRK wo — Timer1 PWM Software Trigger Brake Control Register
  fields as TIMER0_PWMSWBRK
0x180 TIMER1_PWMINTEN0 — Timer1 PWM Interrupt Enable Register 0
  fields as TIMER0_PWMINTEN0
0x184 TIMER1_PWMINTEN1 — Timer1 PWM Interrupt Enable Register 1
  fields as TIMER0_PWMINTEN1
0x188 TIMER1_PWMINTSTS0 — Timer1 PWM Interrupt Status Register 0
  fields as TIMER0_PWMINTSTS0
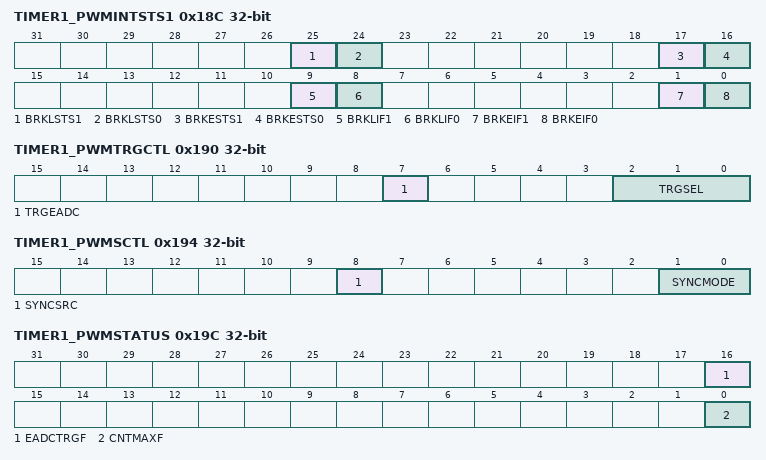
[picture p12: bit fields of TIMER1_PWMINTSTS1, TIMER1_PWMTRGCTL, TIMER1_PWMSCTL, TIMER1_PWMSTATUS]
0x18C TIMER1_PWMINTSTS1 — Timer1 PWM Interrupt Status Register 1
  fields as TIMER0_PWMINTSTS1
0x190 TIMER1_PWMTRGCTL — Timer1 PWM Trigger Control Register
  fields as TIMER0_PWMTRGCTL
0x194 TIMER1_PWMSCTL — Timer1 PWM Synchronous Control Register
  fields as TIMER0_PWMSCTL
0x19C TIMER1_PWMSTATUS
  fields as TIMER0_PWMSTATUS
0x1A0 TIMER1_PWMPBUF ro — Timer1 PWM Period Buffer Register
  fields as TIMER0_PWMPBUF
0x1A4 TIMER1_PWMCMPBUF ro — Timer1 PWM Comparator Buffer Register
  fields as TIMER0_PWMCMPBUF
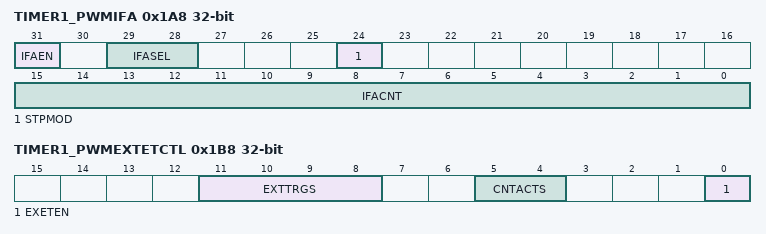
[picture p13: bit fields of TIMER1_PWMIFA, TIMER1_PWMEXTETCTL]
0x1A8 TIMER1_PWMIFA — Timer1 PWM Interrupt Flag Accumulator Register
  fields as TIMER0_PWMIFA
0x1AC TIMER1_PWMAINTSTS — Timer1 PWM Accumulator Interrupt Flag Register
  fields as TIMER0_PWMAINTSTS
0x1B0 TIMER1_PWMAINTEN — Timer1 PWM Accumulator Interrupt Enable Register
  fields as TIMER0_PWMAINTEN
0x1B4 TIMER1_PWMAPDMACTL — Timer1 PWM Accumulator PDMA Control Register
  fields as TIMER0_PWMAPDMACTL
0x1B8 TIMER1_PWMEXTETCTL — Timer1 PWM External Event Trigger Control Register
  fields as TIMER0_PWMEXTETCTL
